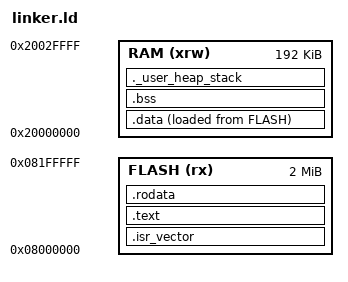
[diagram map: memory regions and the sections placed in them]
/*
******************************************************************************
**
** @file        : linker.ld
**
** @author      : Auto-generated by STM32CubeIDE
**
** @brief       : Linker script for STM32F429ZITx Device from STM32F4 series
**                      2048Kbytes FLASH
**                      64Kbytes CCMRAM
**                      192Kbytes RAM
**
**                Set heap size, stack size and stack location according
**                to application requirements.
**
**                Set memory bank area and size if external memory is used
**
**  Target      : STMicroelectronics STM32
**
**  Distribution: The file is distributed as is, without any warranty
**                of any kind.
**
******************************************************************************
** @attention
**
** Copyright (c) 2022 STMicroelectronics.
** All rights reserved.
**
** This software is licensed under terms that can be found in the LICENSE file
** in the root directory of this software component.
** If no LICENSE file comes with this software, it is provided AS-IS.
**
******************************************************************************
*/

ENTRY(reset_handler)

_estack = 0x20030000;

/* throw a link error if heap and stack don't fit into RAM */
_min_heap_size = 0x200;;
_min_stack_size = 0x400;;

/* specify the memory areas */
MEMORY
{
  FLASH (rx)  : ORIGIN = 0x08000000, LENGTH = 2048K
  RAM (xrw)   : ORIGIN = 0x20000000, LENGTH = 192K
}

/* specify how to layout the program sections in memory */
SECTIONS
{
  /* startup code goes first into FLASH */
  .isr_vector :
  {
    . = ALIGN(4);
    *(.isr_vector)
    . = ALIGN(4);
  } >FLASH

  /* then program code and other data goes into FLASH */
  .text :
  {
    . = ALIGN(4);
    *(.text)
    *(.text*)
    . = ALIGN(4);
  } >FLASH

  /* next, constant data goes into FLASH */
  .rodata :
  {
    . = ALIGN(4);
    *(.rodata)
    *(.rodata*)
    . = ALIGN(4);
  } >FLASH

  /* used by the startup to initialize data */
  _sidata = LOADADDR(.data);

  /* initialized data is in flash but will be moved to RAM */
  .data :
  {
    . = ALIGN(4);
    _sdata = .;
    *(.data)
    *(.data*)
    . = ALIGN(4);
    _edata = .;
  } >RAM AT> FLASH

  /*  */
  . = ALIGN(4);
  .bss :
  {
    _sbss = .;
    __bss_start__ = _sbss;
    *(.bss)
    *(.bss*)
    *(COMMON)

    . = ALIGN(4);
    _ebss = .;
    __bss_end__ = _ebss;
  } >RAM

  /* ensure we have enough space leftover for the heap and the stack */
  ._user_heap_stack :
  {
    . = ALIGN(8);
    . = . + _min_heap_size;
    . = . + _min_stack_size;
    . = ALIGN(8);
  } >RAM

  /* contains attributes of the build */
  .ARM.attributes 0 : { *(.ARM.attributes) }
}
